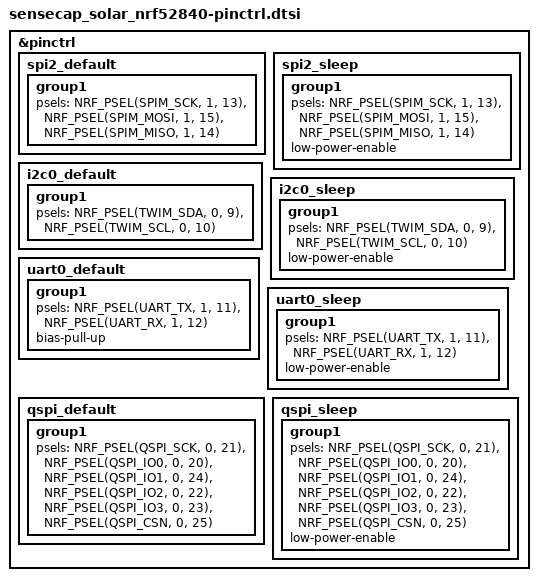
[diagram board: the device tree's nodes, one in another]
/*
 * Seeed SenseCAP Solar Node (P1 / P1-Pro) — pin control
 * SPDX-License-Identifier: Apache-2.0
 *
 * MeshCore variants/sensecap_solar variant.cpp:
 * - SPI2 (SX1262): SCK=P1.13, MOSI=P1.15, MISO=P1.14
 * - I2C0 (Grove): SDA=P0.09, SCL=P0.10
 * - UART0 (L76): TX=P1.11, RX=P1.12
 * - QSPI: SCK=P0.21, CS=P0.25, IO0-3=P0.20,24,22,23
 */

&pinctrl {
	spi2_default: spi2_default {
		group1 {
			psels = <NRF_PSEL(SPIM_SCK, 1, 13)>,
				<NRF_PSEL(SPIM_MOSI, 1, 15)>,
				<NRF_PSEL(SPIM_MISO, 1, 14)>;
		};
	};

	spi2_sleep: spi2_sleep {
		group1 {
			psels = <NRF_PSEL(SPIM_SCK, 1, 13)>,
				<NRF_PSEL(SPIM_MOSI, 1, 15)>,
				<NRF_PSEL(SPIM_MISO, 1, 14)>;
			low-power-enable;
		};
	};

	i2c0_default: i2c0_default {
		group1 {
			psels = <NRF_PSEL(TWIM_SDA, 0, 9)>,
				<NRF_PSEL(TWIM_SCL, 0, 10)>;
		};
	};

	i2c0_sleep: i2c0_sleep {
		group1 {
			psels = <NRF_PSEL(TWIM_SDA, 0, 9)>,
				<NRF_PSEL(TWIM_SCL, 0, 10)>;
			low-power-enable;
		};
	};

	uart0_default: uart0_default {
		group1 {
			psels = <NRF_PSEL(UART_TX, 1, 11)>,
				<NRF_PSEL(UART_RX, 1, 12)>;
			bias-pull-up;
		};
	};

	uart0_sleep: uart0_sleep {
		group1 {
			psels = <NRF_PSEL(UART_TX, 1, 11)>,
				<NRF_PSEL(UART_RX, 1, 12)>;
			low-power-enable;
		};
	};

	qspi_default: qspi_default {
		group1 {
			psels = <NRF_PSEL(QSPI_SCK, 0, 21)>,
				<NRF_PSEL(QSPI_IO0, 0, 20)>,
				<NRF_PSEL(QSPI_IO1, 0, 24)>,
				<NRF_PSEL(QSPI_IO2, 0, 22)>,
				<NRF_PSEL(QSPI_IO3, 0, 23)>,
				<NRF_PSEL(QSPI_CSN, 0, 25)>;
		};
	};

	qspi_sleep: qspi_sleep {
		group1 {
			psels = <NRF_PSEL(QSPI_SCK, 0, 21)>,
				<NRF_PSEL(QSPI_IO0, 0, 20)>,
				<NRF_PSEL(QSPI_IO1, 0, 24)>,
				<NRF_PSEL(QSPI_IO2, 0, 22)>,
				<NRF_PSEL(QSPI_IO3, 0, 23)>,
				<NRF_PSEL(QSPI_CSN, 0, 25)>;
			low-power-enable;
		};
	};
};
